# IND83215A register map
Series: Verne; File version: A0
CPU: CM0 r0p1, selectable endian, no MPU, no FPU, 4 interrupt priority bits
Registers are 32-bit, read-write, no defined reset value unless marked. A register's access mark holds for its fields unless they carry their own. Offsets are from the block's base; [hi:lo] are bit positions; lines under a group give offsets from that group.

## IOCTRLA — I/O configuration and DFT pin control
Base 0x50000C00; register names take the prefix IOCTRLA_
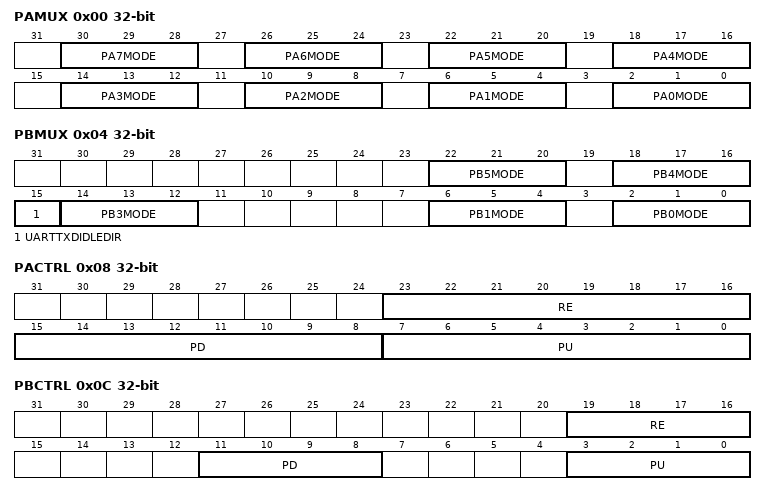
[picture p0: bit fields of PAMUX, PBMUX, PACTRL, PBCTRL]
0x00 PAMUX — Port A Function Configuration
  [30:28] PA7MODE — Pin Mux for PA7 0x0: GPA[7]. 'GPIO Barium' reads and writes data to the GPIO. Output Enable is controlled by GPIO Barium via the direction bit. Read Enable, Pull-Up, and Pull-Down are controlled by register in IOCTRLA. 0x1: LINM_Txd is driven by GPIO instead of internal LIN Core 0x2: UART Signle wire mode.NOTE:need to enable the Pullup. 0x3: UART Rxd. 0x4: Output of the 1st stage Glitch filter of LINS_Rxd. 0x5: TEST_MUX7. 'Digital Testmux' writes data to the GPIO. DEBUG Access must be enabled in the system control block to allow testmux outputs. 0x6: External LinPhy, Input LINS Rxd from GPIO. 0x7: PWM Mode. PWM Aux Channel 2 writes data to the GPIO.
  [26:24] PA6MODE — Pin Mux for PA6 0x0: GPA[6]. 'GPIO module' reads and writes data to the GPIO. Output Enable is controlled by GPIO module via the direction bit. Read Enable, Pull-Up, and Pull-Down are controlled by PACTRL register. 0x1: Reserved. 0x4: GT4INB. 0x3: SS. 0x5: CT3INC. 0x6: GT1EXTF. 0x7: PAUX[0].
  [22:20] PA5MODE — Pin Mux for PA5 0x0: GPA[5]. 'GPIO Barium' reads and writes data to the GPIO. Output Enable is controlled by GPIO Barium via the direction bit. Read Enable, Pull-Up, and Pull-Down are controlled by register in IOCTRLA. 0x1: Input of LINS core Rxd. 0x2: UART Rxd from GPIO. 0x3: SPI MISO. 0x4: Input of LINM core Rxd. 0x5: Output of the 1st stage Glitch filter of LINM_Rxd. 0x6: TEST_MUX5. 'Digital Testmux' writes data to the GPIO. DEBUG Access must be enabled in the system control block to allow testmux outputs. 0x7: PWM Mode. PWM Aux Channel 0 writes data to the GPIO.
  [18:16] PA4MODE — Pin Mux for PA4 0x0: GPA[4]. 'GPIO Barium' reads and writes data to the GPIO. Output Enable is controlled by GPIO Barium via the direction bit. Read Enable, Pull-Up, and Pull-Down are controlled by register in IOCTRLA. 0x1: Output of the 3rd stage Glitch filter of LINS_Rxd. 0x2: UART Txd to GPIO. 0x3: SPI MOSI. 0x4: Output of the 3rd stage Glitch filter of LINM_Rxd. 0x5: Input of the 1st stage Glitch filter from Internal LIN Master Phy. 0x6: TEST_MUX4. 'Digital Testmux' writes data to the GPIO. DEBUG Access must be enabled in the system control block to allow testmux outputs. 0x7: PWM Mode. PWM Aux Channel 4 writes data to the GPIO.
  [14:12] PA3MODE — Pin Mux for PA3 0x0: GPA[3]. 'GPIO Barium' reads and writes data to the GPIO. Output Enable is controlled by GPIO Barium via the direction bit. Read Enable, Pull-Up, and Pull-Down are controlled by GPIO register in IOCTRLA. 0x1: Output of the 2nd stage Glitch filter of LINS_Rxd. 0x2: SPI MISO. 0x3: TEST_MUX3. 'Digital Testmux' writes data to the GPIO. DEBUG Access must be enabled in the system control block to allow testmux outputs. 0x4: Output of the 2rd stage Glitch filter of LINM_Rxd. 0x5: Output of the 3rd stage Glitch filter of LINS_Rxd. 0x6: External LinPhy, Input LINM Rxd from GPIO. 0x7: PWM Mode, PWM Aux Channel 3 writes data to the GPIO.
  [10:8] PA2MODE — Pin Mux for PA2 0x0: GPA[2]. 'GPIO Barium' reads and writes data to the GPIO. Output Enable is controlled by GPIO Barium via the direction bit. Read Enable, Pull-Up, and Pull-Down are controlled by GPIO register in IOCTRLA. 0x1: Output of the 1st stage Glitch filter of LINS_Rxd. 0x2: SPI MOSI. 0x3: SPI Master Slave Select Mode. 0x4: TEST_MUX2. 'Digital Testmux' writes data to the GPIO. DEBUG Access must be enabled in the system control block to allow testmux outputs. 0x5: Output of the 2nd stage Glitch filter of LINS_Rxd. 0x6: LINM_Core Txd output to GPIO(connect to External LinPhy) instead of internal LIN PHY. 0x7: PWM Mode, PWM Aux Channel 2 writes data to the GPIO.
  [6:4] PA1MODE — Pin Mux for PA1 0x0: GPA[1]. 'GPIO Barium' reads and writes data to the GPIO. Output Enable is controlled by GPIO Barium via the direction bit. Read Enable, Pull-Up, and Pull-Down are controlled by GPIO register in IOCTRLA. 0x1: TEST_MUX1. 'Digital Testmux' writes data to the GPIO. DEBUG Access must be enabled in the system control block to allow testmux outputs. 0x2: SPI Clock. 0x3: SPI Clock. 0x4: Output of the 1st stage Glitch filter of LINM_Rxd. 0x5: Output of the 1st stage Glitch filter of LINS_Rxd. 0x6: External LinPhy, Input LINS Rxd from GPIO. 0x7: PWM Mode, PWM Aux Channel 1 writes data to the GPIO.
  [2:0] PA0MODE — Pin Mux for PA0 0x0: GPA[0]. 'GPIO Barium' reads and writes data to the GPIO. Output Enable is controlled by GPIO Barium via the direction bit. Read Enable, Pull-Up, and Pull-Down are controlled by register in IOCTRLA. 0x1: Input of the 1st stage Glitch filter from Internal LIN Slave Phy. 0x2: SPI Master Slave Select Mode. 0x3: TEST_MUX0. 'Digital Testmux' writes data to the GPIO. DEBUG Access must be enabled in the system control block to allow testmux outputs. 0x4: Input of the 1st stage Glitch filter from Internal LIN Master Phy. 0x5: Input of the 1st stage Glitch filter from Internal LIN Slave Phy. 0x6: LINS_Core Txd output to GPIO(connect to External LinPhy) instead of internal LIN PHY. 0x7: PWM Mode. PWM Aux Channel 0 writes data to the GPIO.
0x04 PBMUX — Port B Function Configuration
  [22:20] PB5MODE — Pin Mux for PB5 0x0: GPB[5]. 'GPIO Barium' reads and writes data to the GPIO. Output Enable is controlled by GPIO Barium via the direction bit. Read Enable, Pull-Up, and Pull-Down are controlled by register in IOCTRLA. 0x1: LIN Master. 0x2: LINM_Txd is driven by GPIO instead of internal LIN Core 0x3: UART Signle wire mode. 0x4: Reserved 0x5: Reserved 0x6: Reserved 0x7: Reserved
  [18:16] PB4MODE — Pin Mux for PB4 0x0: GPB[4]. 'GPIO Barium' reads and writes data to the GPIO. Output Enable is controlled by GPIO Barium via the direction bit. Read Enable, Pull-Up, and Pull-Down are controlled by register in IOCTRLA. 0x1: LIN Slave. 0x2: LINS_Txd is driven by GPIO instead of internal LIN Core 0x3: UART Signle wire mode. 0x4: Reserved 0x5: Reserved 0x6: Reserved 0x7: Reserved
  [15] UARTTXDIDLEDIR — Control the direction of PAD for UART TXD Idle: 0x0: old the UART TXD Pad to output when TXD is idle. 0x1: Switch the TXD Pad to input When TXD is idle.
  [14:12] PB3MODE — Pin Mux for PB3 0x0: SWD, Serial Wire Debug Data. 0x1: GPB[3]. 'GPIO Barium' reads and writes data to the GPIO. Output Enable is controlled by GPIO Barium via the direction bit. Read Enable, Pull-Up, and Pull-Down are controlled by register in IOCTRLA. 0x2: Reserved 0x3: Reserved 0x4: Reserved 0x5: Reserved 0x6: Reserved 0x7: PWM Mode. PWM Aux Channel 4 writes data to the GPIO.
  [6:4] PB1MODE — Pin Mux for PB1 0x0: GPB[1]. 'GPIO Barium' reads and writes data to the GPIO. Output Enable is controlled by GPIO Barium via the direction bit. Read Enable, Pull-Up, and Pull-Down are controlled by register in IOCTRLA. 0x1: LINM Single wire mode, LINM PHY RXD/LINM PHY TXD, Open-drain output. 0x2: UART Rxd. 0x3: UART Signle wire mode.NOTE:need to enable the Pullup 0x4: TEST_MUX9. 'Digital Testmux' writes data to the GPIO. DEBUG Access must be enabled in the system control block to allow testmux outputs. 0x5: Output of the 3rd stage Glitch filter of LINM_Rxd. 0x6: External LinPhy, Input LINM Rxd from GPIO. 0x7: PWM Mode. PWM Aux Channel 4 writes data to the GPIO.
  [2:0] PB0MODE — Pin Mux for PB0 0x0: GPB[0]. 'GPIO Barium' reads and writes data to the GPIO. Output Enable is controlled by GPIO Barium via the direction bit. Read Enable, Pull-Up, and Pull-Down are controlled by register in IOCTRLA. 0x1: LINS Single wire mode, LINS PHY RXD/LINS PHY TXD, Open-drain output. 0x2: UART Txd. 0x3: UART Signle wire mode.NOTE:need to enable the Pullup 0x4: TEST_MUX8. 'Digital Testmux' writes data to the GPIO. DEBUG Access must be enabled in the system control block to allow testmux outputs. 0x5: Output of the 2nd stage Glitch filter of LINM_Rxd. 0x6: LINM_Core Txd output to GPIO(connect to External LinPhy) instead of internal LIN PHY. 0x7: PWM Mode. PWM Aux Channel 3 writes data to the GPIO.
0x08 PACTRL — PORTA Control. Controls for the pads of GPIO port A
  [23:16] RE — Read enable. Each bit in this register determines whether the read data path is enabled for a pad. Set a bit to enable input data to be the read from the pad.
  [15:8] PD — Pull-down enable. Each bit in this register determines whether the pull-down resistor is enabled for a pad. Set a bit to enable the resistor.
  [7:0] PU — Pull-up enable. Each bit in this register determines whether the pull-up resistor is enabled for a pad.
0x0C PBCTRL — PORTB Control. Controls for the pads of GPIO port B
  [19:16] RE — Read enable. Each bit in this register determines whether the read data path is enabled for a pad. Set a bit to enable input data to be the read from the pad.
  [11:8] PD — Pull-down enable. Each bit in this register determines whether the pull-down resistor is enabled for a pad. Set a bit to enable the resistor.
  [3:0] PU — Pull-up enable. Each bit in this register determines whether the pull-up resistor is enabled for a pad.
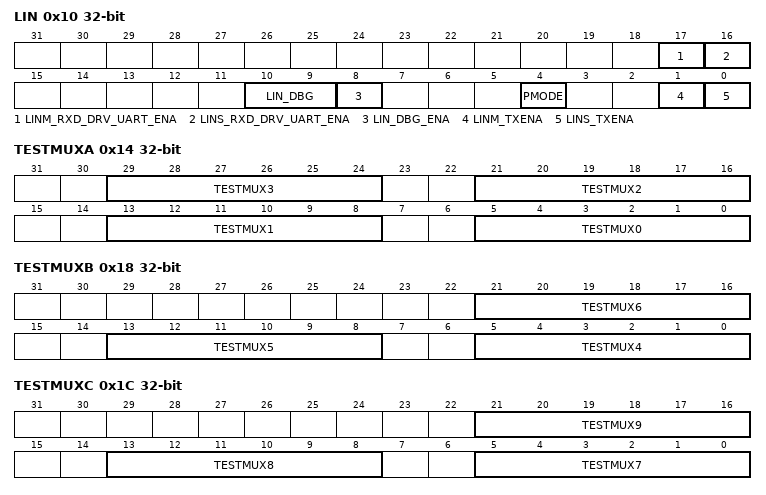
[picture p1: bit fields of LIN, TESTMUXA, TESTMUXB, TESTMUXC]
0x10 LIN — LIN Pin Control.
  [17] LINM_RXD_DRV_UART_ENA — Enable of LIN RXD drives UART Rxd and LIN Core simultaneously.
  [16] LINS_RXD_DRV_UART_ENA — Enable of LIN RXD drives UART Rxd and LIN Core simultaneously.
  [10:9] LIN_DBG — LIN DEBUG. 0x0: lin_tx_s_duty_ibg1up_tp to PA[0] analog channel 0x1: lin_tx_s_slope_ibg1up_tp to PA[0] analog channel 0x2: lin_tx_m_duty_ibg1up_tp to PA[0] analog channel 0x3: lin_tx_m_slope_ibg1up_tp to PA[0] analog channel
  [8] LIN_DBG_ENA — LIN DEBUG enable.
  [4] PMODE — LIN Power Mode. Control LINS power state in hibernate mode. 0x0: Regardless of the related enable bits, LIN TX analog parts will be shut-down in hibernate mode, unless any LIN dominant signal is detected. 0x1: LIN TX analog parts are still controlled by theirs corresponding enable bits.
  [1] LINM_TXENA — LIN transmit enable.
  [0] LINS_TXENA — LIN transmit enable.
0x14 TESTMUXA — Test mux select of group A.
  [29:24] TESTMUX3 — Selects debug signal to be output on the port when the port is configured to TEST_MUX3 mode. Refer to TEST_MUX0 for signal selection
  [21:16] TESTMUX2 — Selects debug signal to be output on the port when the port is configured to TEST_MUX2 mode. Refer to TEST_MUX0 for signal selection
  [13:8] TESTMUX1 — Selects debug signal to be output on the port when the port is configured to TEST_MUX1 mode. Refer to TEST_MUX0 for signal selection
  [5:0] TESTMUX0 — Selects debug signal to be output on the port when the port is configured to TEST_MUX0 mode. 0x0: LIN Slave Output of 1st Stage Rxd Glitch Filter 0x1: LIN Slave Output of 2nd Stage Rxd Glitch Filter 0x2: LIN Slave Output of 3rd Stage Rxd Glitch Filter 0x3: LIN Slave PHY's Rxd Monitor 0x4: LIN Slave PHY's Txd Monitor. 0x5: LIN Slave Input of Core rxd 0x6: LIN Slave Output of Core txd 0x7: LIN Master Output of 1st Stage Rxd Glitch Filter 0x8: LIN Master Output of 2nd Stage Rxd Glitch Filter 0x9: LIN Master Output of 3rd Stage Rxd Glitch Filter 0xa: LIN Master PHY's Rxd Monitor 0xb: LIN Master PHY's Txd Monitor. 0xc: LIN Master Input of Core rxd 0xd: LIN Master Output of Core txd 0xe: PMUA (Power Management Unit Asic) QACK 0xf: PMUA (Power Management Unit Asic) Wakeup signal 0x10: PMUA (Power Management Unit Asic) snowflake 0x11: BATTERY VOLTAGE MONITOR vbat_low 0x12: BATTERY VOLTAGE MONITOR vbat_high 0x13: BATTERY VOLTAGE MONITOR vbat_low_flag 0x14: BATTERY VOLTAGE MONITOR vbat_high_flag 0x15: BATTERY VOLTAGE MONITOR vbat_low_dbnc 0x16: BATTERY VOLTAGE MONITOR vbat_high_dbnc 0x17: BOR bor_control state[0] 0x18: BOR bor_control state[1] 0x19: BOR bor_bias_ena 0x1a: BOR bor_bias_ena_l 0x1b: BOR CONTROL STATE MACHINE pmua_bor_bias_ena 0x1c: BOR CONTROL STATE MACHINE hf_clk_allowed 0x1d: BOR CONTROL STATE MACHINE hf_active 0x1e: BOR CONTROL STATE MACHINE pmua_bor_arm_sync 0x1f: CRGA (Clock Reset Generation Asic) (scan_test_mode | lf_rc_clk) 0x20: CRGA (Clock Reset Generation Asic) (scan_test_mode | hf_rc_clk) 0x21: CRGA (Clock Reset Generation Asic) (scan_test_mode | lf_rc_sts) 0x22: CRGA (Clock Reset Generation Asic) (scan_test_mode | hf_rc_sts) 0x23: CRGA (Clock Reset Generation Asic) (scan_test_mode | clk_sys_gated) 0x24: CRGA (Clock Reset Generation Asic) (a_por_n) 0x25: CRGA (Clock Reset Generation Asic) (bor_3v3_n) 0x26: CRGA (Clock Reset Generation Asic) (ovtemp_flag) 0x27: CRGA (Clock Reset Generation Asic) (bor_1v5_n) 0x28: CRGA (Clock Reset Generation Asic) (wdt_bark) 0x29: ADC Controller sar_ana_clk 0x2a: ADC Controller adc_start_del 0x2b: ADC Controller sar_smp_vcm 0x2c: Flash Controller 4Mhz OSCw 0x2d: Flash Controller flash TDO 0x2e: Flash Controller flash TDI 0x2f: Flash Controller flash CLK
0x18 TESTMUXB — Test mux select of group B.
  [21:16] TESTMUX6 — Selects debug signal to be output on the port when the port is configured to TEST_MUX3 mode. Refer to TEST_MUX0 for signal selection
  [13:8] TESTMUX5 — Selects debug signal to be output on the port when the port is configured to TEST_MUX3 mode. Refer to TEST_MUX0 for signal selection
  [5:0] TESTMUX4 — Selects debug signal to be output on the port when the port is configured to TEST_MUX3 mode. Refer to TEST_MUX0 for signal selection
0x1C TESTMUXC — Test mux select of group C.
  [21:16] TESTMUX9 — Selects debug signal to be output on the port when the port is configured to TEST_MUX3 mode. Refer to TEST_MUX0 for signal selection
  [13:8] TESTMUX8 — Selects debug signal to be output on the port when the port is configured to TEST_MUX3 mode. Refer to TEST_MUX0 for signal selection
  [5:0] TESTMUX7 — Selects debug signal to be output on the port when the port is configured to TEST_MUX3 mode. Refer to TEST_MUX0 for signal selection
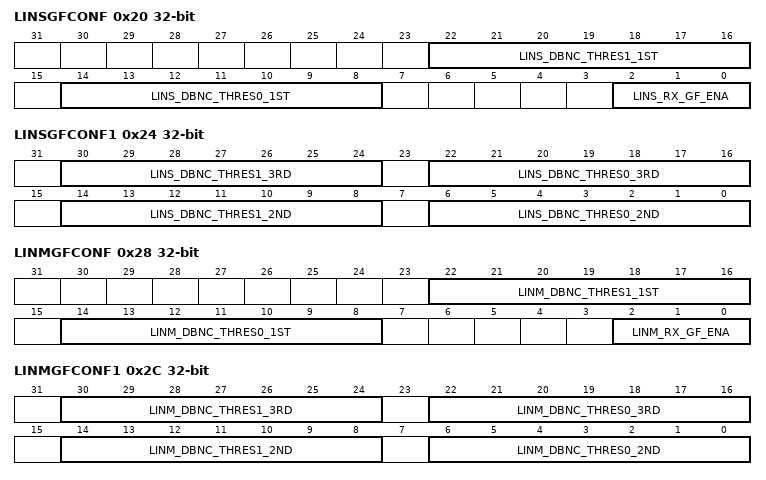
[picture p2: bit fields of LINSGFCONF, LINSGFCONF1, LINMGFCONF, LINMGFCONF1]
0x20 LINSGFCONF — LINS Glitch Filter Configuration in active mode
  [22:16] LINS_DBNC_THRES1_1ST — 1st Stage LINS Debounce Threshold for 0 to 1. 1st Stage LINS Debounce Threshold for 0 to 1, detect '1' width of (T_clksys*resetvalue = 62.5ns*0 = 0[us].
  [14:8] LINS_DBNC_THRES0_1ST — 1st Stage LINS Debounce Threshold for 1 to 0. 1st Stage LINS Debounce Threshold for 1 to 0, detect '0' width of (T_clksys*resetvalue = 62.5ns*8 = 0.5[us].
  [2:0] LINS_RX_GF_ENA — LINS RXD Glitch Filter enables. bit-0: Enable LINS Glitch Filter 1st stage; bit-1: Enable LINS Glitch Filter 2nd stage; bit-2: Enable LINS Glitch Filter 3rd stage; NOTE: The write operation of this register takes effect by configuring SYSCTRLA_SFRS->TRIM_ACCESS_KEY.TRIM_ACCESS_KEY, FILT_ACCESS.FILT_UNLOCK
0x24 LINSGFCONF1 — LINS Glitch Filter Configuration in active mode
  [30:24] LINS_DBNC_THRES1_3RD — 3rd Stage LINS Debounce Threshold for 0 to 1. 3rd Stage LINS Debounce Threshold for 0 to 1, detect '1' width of (T_clksys*resetvalue = 62.5ns*40 = 2.5[us].
  [22:16] LINS_DBNC_THRES0_3RD — 3rd Stage LINS Debounce Threshold for 1 to 0. 3rd Stage LINS Debounce Threshold for 1 to 0, detect '0' width of (T_clksys*resetvalue = 62.5ns*40 = 2.5[us].
  [14:8] LINS_DBNC_THRES1_2ND — 2nd Stage LINS Debounce Threshold for 0 to 1. 2nd Stage LINS Debounce Threshold for 0 to 1, detect '1' width of (T_clksys*resetvalue = 62.5ns*32 = 2[us].
  [6:0] LINS_DBNC_THRES0_2ND — 2nd Stage LINS Debounce Threshold for 1 to 0. 2nd Stage LINS Debounce Threshold for 1 to 0, detect '0' width of (T_clksys*resetvalue = 62.5ns*16 = 1[us].
0x28 LINMGFCONF — LINM Glitch Filter Configuration in active mode.
  [22:16] LINM_DBNC_THRES1_1ST — LINM Debounce Threshold for 0 to 1. 1st Stage LINM Debounce Threshold for 0 to 1, detect '1' width of (T_clksys*resetvalue = 62.5ns*0 = 0[us].
  [14:8] LINM_DBNC_THRES0_1ST — LINM Debounce Threshold for 1 to 0. 1st Stage LINM Debounce Threshold for 1 to 0, detect '0' width of (T_clksys*resetvalue = 62.5ns*8 = 0.5[us].
  [2:0] LINM_RX_GF_ENA — LINM RXD Glitch Filter enables. bit-0: Enable LINM Glitch Filter 1st stage; bit-1: Enable LINM Glitch Filter 2nd stage; bit-2: Enable LINM Glitch Filter 3rd stage; NOTE: The write operation of this register takes effect by configuring SYSCTRLA_SFRS->TRIM_ACCESS_KEY.TRIM_ACCESS_KEY, FILT_ACCESS.FILT_UNLOCK
0x2C LINMGFCONF1 — LINM Glitch Filter Configuration in active mode.
  [30:24] LINM_DBNC_THRES1_3RD — 3rd Stage LINM Debounce Threshold for 0 to 1. 3rd Stage LINM Debounce Threshold for 0 to 1, detect '1' width of (T_clksys*resetvalue = 62.5ns*40 = 2.5[us].
  [22:16] LINM_DBNC_THRES0_3RD — 3rd Stage LINM Debounce Threshold for 1 to 0. 3rd Stage LINM Debounce Threshold for 1 to 0, detect '0' width of (T_clksys*resetvalue = 62.5ns*40 = 2.5[us].
  [14:8] LINM_DBNC_THRES1_2ND — 2nd Stage LINM Debounce Threshold for 0 to 1. 2nd Stage LINM Debounce Threshold for 0 to 1, detect '1' width of (T_clksys*resetvalue = 62.5ns*32 = 2[us].
  [6:0] LINM_DBNC_THRES0_2ND — 2nd Stage LINM Debounce Threshold for 1 to 0. 2nd Stage LINM Debounce Threshold for 1 to 0, detect '0' width of (T_clksys*resetvalue = 62.5ns*16 = 1[us].
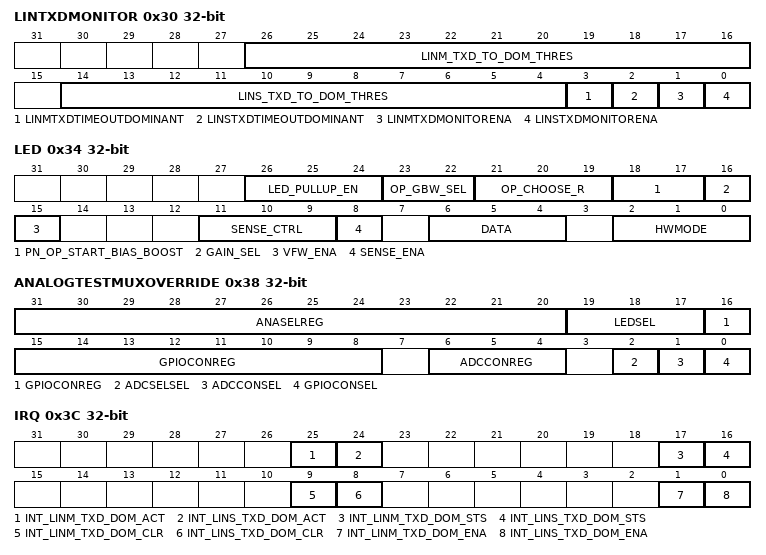
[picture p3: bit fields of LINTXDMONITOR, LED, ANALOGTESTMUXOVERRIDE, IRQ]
0x30 LINTXDMONITOR — LIN TXD Dominant Timeout.
  [26:16] LINM_TXD_TO_DOM_THRES — LINS TxD monitor Threshold to detect LIN bus dominant '0' width of (T_clksys*resetvalue = 62.5us*1024 = 64[ms].
  [14:4] LINS_TXD_TO_DOM_THRES — LINS TxD monitor Threshold to detect LIN bus dominant '0' width of (T_clksys*resetvalue = 62.5us*1024 = 64[ms].
  [3] LINMTXDTIMEOUTDOMINANT ro — Tx Dominant Timeout. The bit is set by LINM TxD monitor if LINM's TxD is stuck at dominant output for 64ms. A dominant to recessive transition of the TxD will clear this bit. LIN's TX will be disabled automatically when this bit is set.
  [2] LINSTXDTIMEOUTDOMINANT — Tx Dominant Timeout. The bit is set by LINS TxD monitor if LINS's TxD is stuck at dominant output for 64ms. A dominant to recessive transition of the TxD will clear this bit. LIN's TX will be disabled automatically when this bit is set.
  [1] LINMTXDMONITORENA — LINM TxD Monitor enable.
  [0] LINSTXDMONITORENA — LINS TxD Monitor enable.
0x34 LED — LED Pin Control.
  [26:24] LED_PULLUP_EN — LED PULLUP ENABLE. LED PAD Pullup enable, ONE HOT code. 0x1: LED0 PAD pullup to PRE5V through a diode and a 50K resistor 0x2: LED1 PAD pullup to PRE5V through a diode and a 50K resistor 0x4: LED2 PAD pullup to PRE5V through a diode and a 50K resistor
  [23:22] OP_GBW_SEL — LED SENSE OP GBW SEL. PN detect fully differential Op GBW choose 00: 3M 01: 5M 10: 8M 11: 10M
  [21:19] OP_CHOOSE_R — LED SENSE OP CHOOSE R. choose nulling resistor to do frequency compensation. Which denpends on the bandwidth of the OP. R<2:0> R GBW<1:0>(CL=3pF) 000 0.5K 11(10M) 001 2.5K 10(8M) 01(5M) 010 4.5K 011 6.5K 11(3M) 100 8.5K 101 10.5K 110 12.5K 111 14.5K
  [18:17] PN_OP_START_BIAS_BOOST — PN OP START BIAS BOOST. PN diff OP start bias current 00: 250nA 01: 500nA 10: 750nA 11: 1uA
  [16] GAIN_SEL — LED Sense AFE gain select. V_ADC = (vbat-vled)*GAIN , where V_ADC is voltage to ADC LED channle, and GAIN is selected by GAIN_SEL as following(typical value): 0x0: GAIN = 1/2 0x1: GAIN = 1/4
  [15] VFW_ENA — LED Forward Voltage Current Enable. Set to enable the independent LED VFW current source(maximum=5mA). When ADC CH2 measurement is active, the LED channel selected by CH2_SEL will be driven by LED_VFW current source.
  [11:9] SENSE_CTRL — LED. LED Sense Control bits for override control/debug.
  [8] SENSE_ENA — LED Forward Voltage Sense Enable. Set to enable LED forward voltage sense module. After setting this bit, it's recommended to wait ~40us before ADC conversion for LED_SENSE to settle down.
  [6:4] DATA — LED Data Out. When the LED hardware mode is disabled, then the data in this register bit is used to drive the LED driver. Each bit controls the corresonding LED Channel respectively.
  [2:0] HWMODE — LED hardware mode. LED Hardware Mode Enable. Each bit controls the corresponding LED Channel respectively. 0x0: Hardware Mode Disabled. LED_DATA register drives the LED Data Output pin. Read is not available on this pin. 0x1: Hardware Mode Enabled. PWM_BARIUM peripheral drives the LED Data Output pin. Read is not available on this pin.
0x38 ANALOGTESTMUXOVERRIDE
  [31:20] ANASELREG — Firmware Debug Value. need to be configured TOGETHER WITH GPIO_CON_REG to enable PA PAD output. (ADC_SEL_SEL also need to be set to 1) 0x1: Enable PA[0] analog connection to ADC 0x2: Enable PA[1] analog connection to ADC 0x4: Enable PA[2] analog connection to ADC 0x8: Enable PA[3] analog connection to ADC 0x10: Enable PA[4] analog connection to ADC 0x20: Enable PA[5] analog connection to ADC 0x40: Enable PA[6] analog connection to ADC 0x80: Enable PA[7] analog connection to ADC 0x100: Enable PB[0] analog connection to ADC 0x200: Enable PB[1] analog connection to ADC 0x400: Reserved 0x800: Enable PB[3] analog connection to ADC
  [19:17] LEDSEL — Firmware Debug Value. 0x1: Enable LED0 analog connection for short to gnd detecting 0x2: Enable LED1 analog connection for short to gnd detecting 0x4: Enable LED2 analog connection for short to gnd detecting
  [16:8] GPIOCONREG — Firmware Debug Value. GPIO test MUX select 0x1: Select VDD3V3 to PA0 0x2: Select VDD1V5 to PA0 0x4: Select VDD_PRE5V*1/4 to PA0 0x8: Select VBG_1P2V to PA1 0x10: Select VBG_BUF to PA1 0x20: Select VREF_1P1 to PA1 0x40: Select tempsensor to PA1 0x80: Select ADC_REFP to PA1 0x100: Select BOR_REF from PA1, for BOR trig point test
  [6:4] ADCCONREG — Firmware Debug Value. Contains the output value when the ADC_CON_SEL firmware select bit is set 0x1: Select LED0 Forward Voltage for measurement 0x2: Select LED1 Forward Voltage for measurement 0x4: Select LED2 Forward Voltage for measurement
  [2] ADCSELSEL — Hardware/Firmware Select. 0x0: Hardware Controlled. 0x1: ADC_SEL_REG controls output.
  [1] ADCCONSEL — ADC CON SEL. 0x0: Hardware Controlled. 0x1: ADC_CON_REG controls output.
  [0] GPIOCONSEL — ardware/Firmware Select. 0x0: Hardware Controlled. 0x1: GPIO_CON_REG controls output.
0x3C IRQ — IOCTRLA LINS/LINM TXD Dominant Monitor interrupts. Contains the the enable, clear, status and active flag for the LINS/LINM TXD Dominant Monitor interrupt sources.
  [25] INT_LINM_TXD_DOM_ACT ro — LINM TXD Dominant Monitor interrupt active.
  [24] INT_LINS_TXD_DOM_ACT ro — LINS TXD Dominant Monitor interrupt active.
  [17] INT_LINM_TXD_DOM_STS ro — LINM TXD Dominant Monitor interrupt status.
  [16] INT_LINS_TXD_DOM_STS ro — LINS TXD Dominant Monitor interrupt status.
  [9] INT_LINM_TXD_DOM_CLR wo — LINM TXD Dominant Monitor interrupt clear. Autoclear: includes a synchronous reset signal which clears the register on the cycle following write.
  [8] INT_LINS_TXD_DOM_CLR wo — LINS TXD Dominant Monitor interrupt clear. Autoclear: includes a synchronous reset signal which clears the register on the cycle following write.
  [1] INT_LINM_TXD_DOM_ENA — LINM TXD Dominant Monitor interrupt enable.
  [0] INT_LINS_TXD_DOM_ENA — LINS TXD Dominant Monitor interrupt enable.
0x40 FILT_ACCESS — Glitch Filter access key
  [31] FILT_UNLOCK — Set Only bit. Write 1 to this bit to un-lock FILT_CODE bits.
